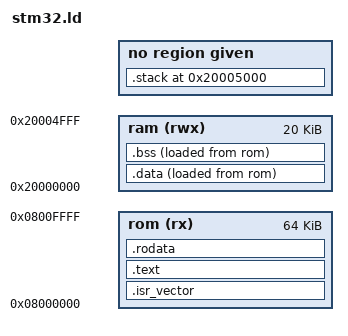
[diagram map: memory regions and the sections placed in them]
ENTRY(Reset_Handler)
MEMORY
{
  ram (rwx) : ORIGIN = 0x20000000, LENGTH = 20K
  rom (rx)  : ORIGIN = 0x08000000, LENGTH = 64K
}
SECTIONS
{

    /* The startup code into ROM memory */
    .isr_vector :
    {
        . = ALIGN(4);
        KEEP(*(.isr_vector)) /* Startup code */
        . = ALIGN(4);
    } >rom

    /* The program code and other data into ROM memory */
    .text :
    {
        . = ALIGN(4);
        *(.text)           /* .text sections (code) */
        *(.text_startup1)   /* .text* sections (code) */
        *(.text_startup2)   /* .text* sections (code) */
        *(.text*)          /* .text* sections (code) */
        *(.glue_7)         /* glue arm to thumb code */
        *(.glue_7t)        /* glue thumb to arm code */
        *(.eh_frame)

        KEEP (*(.init))
        KEEP (*(.fini))

        . = ALIGN(4);
        _etext = .;        /* define a global symbols at end of code */
    } >rom

    /* Constant data into ROM memory*/
    .rodata :
    {
        . = ALIGN(4);
        *(.rodata)         /* .rodata sections (constants, strings, etc.) */
        *(.rodata*)        /* .rodata* sections (constants, strings, etc.) */
        . = ALIGN(4);
    } >rom
    /*不是太明白，_sidata的地址就是 .data的 LMA地址， */
    /* Used by the startup to initialize data */
     _sidata = LOADADDR(.data);
    .data : 
    {
        . = ALIGN(4);
        _sdata = .;        /* create a global symbol at data start */
        *(.data)           /* .data sections */
        *(.data*)          /* .data* sections */

        . = ALIGN(4);
        _edata = .;        /* define a global symbol at data end */
    } >ram AT > rom

    /* Uninitialized data section into RAM memory */
    . = ALIGN(4);
    .bss :
    {
        /* This is used by the startup in order to initialize the .bss secion */
        _sbss = .;         /* define a global symbol at bss start */
        __bss_start__ = _sbss;
        *(.bss)
        *(.bss*)
        *(COMMON)

        . = ALIGN(4);
        _ebss = .;         /* define a global symbol at bss end */
        __bss_end__ = _ebss;
    } >ram AT > rom
	.stack   0x20005000 :
	{
		_estack = .;
		*(.stack)
	}

    /* Remove information from the compiler libraries */
    /DISCARD/ :
    {
        libc.a ( * )
        libm.a ( * )
        libgcc.a ( * )
    }
} 
